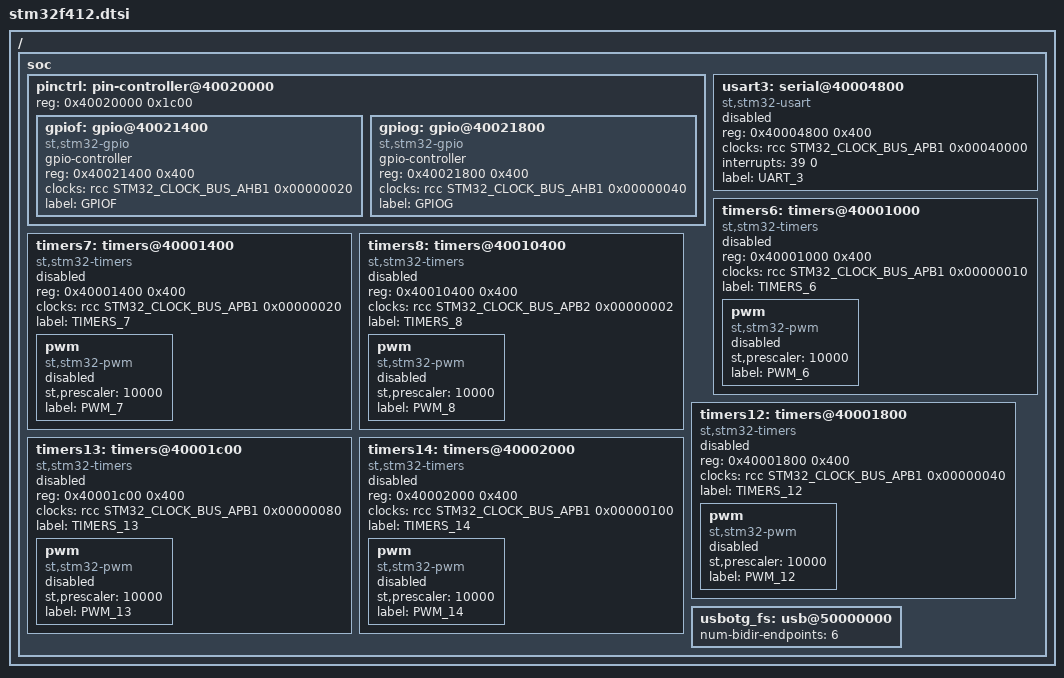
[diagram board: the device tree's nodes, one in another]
/*
 * Copyright (c) 2017 Florian Vaussard, HEIG-VD
 *
 * SPDX-License-Identifier: Apache-2.0
 */

#include <st/stm32f412-pinctrl.dtsi>
#include <st/stm32f411.dtsi>

/ {
	soc {
		pinctrl: pin-controller@40020000 {
			reg = <0x40020000 0x1c00>;

			gpiof: gpio@40021400 {
				compatible = "st,stm32-gpio";
				gpio-controller;
				#gpio-cells = <2>;
				reg = <0x40021400 0x400>;
				clocks = <&rcc STM32_CLOCK_BUS_AHB1 0x00000020>;
				label = "GPIOF";
			};

			gpiog: gpio@40021800 {
				compatible = "st,stm32-gpio";
				gpio-controller;
				#gpio-cells = <2>;
				reg = <0x40021800 0x400>;
				clocks = <&rcc STM32_CLOCK_BUS_AHB1 0x00000040>;
				label = "GPIOG";
			};
		};

		usart3: serial@40004800 {
			compatible = "st,stm32-usart", "st,stm32-uart";
			reg = <0x40004800 0x400>;
			clocks = <&rcc STM32_CLOCK_BUS_APB1 0x00040000>;
			interrupts = <39 0>;
			status = "disabled";
			label = "UART_3";
		};

		timers6: timers@40001000 {
			compatible = "st,stm32-timers";
			reg = <0x40001000 0x400>;
			clocks = <&rcc STM32_CLOCK_BUS_APB1 0x00000010>;
			status = "disabled";
			label = "TIMERS_6";

			pwm {
				compatible = "st,stm32-pwm";
				status = "disabled";
				st,prescaler = <10000>;
				label = "PWM_6";
			};
		};

		timers7: timers@40001400 {
			compatible = "st,stm32-timers";
			reg = <0x40001400 0x400>;
			clocks = <&rcc STM32_CLOCK_BUS_APB1 0x00000020>;
			status = "disabled";
			label = "TIMERS_7";

			pwm {
				compatible = "st,stm32-pwm";
				status = "disabled";
				st,prescaler = <10000>;
				label = "PWM_7";
			};
		};

		timers8: timers@40010400 {
			compatible = "st,stm32-timers";
			reg = <0x40010400 0x400>;
			clocks = <&rcc STM32_CLOCK_BUS_APB2 0x00000002>;
			status = "disabled";
			label = "TIMERS_8";

			pwm {
				compatible = "st,stm32-pwm";
				status = "disabled";
				st,prescaler = <10000>;
				label = "PWM_8";
			};
		};

		timers12: timers@40001800 {
			compatible = "st,stm32-timers";
			reg = <0x40001800 0x400>;
			clocks = <&rcc STM32_CLOCK_BUS_APB1 0x00000040>;
			status = "disabled";
			label = "TIMERS_12";

			pwm {
				compatible = "st,stm32-pwm";
				status = "disabled";
				st,prescaler = <10000>;
				label = "PWM_12";
			};
		};

		timers13: timers@40001c00 {
			compatible = "st,stm32-timers";
			reg = <0x40001c00 0x400>;
			clocks = <&rcc STM32_CLOCK_BUS_APB1 0x00000080>;
			status = "disabled";
			label = "TIMERS_13";

			pwm {
				compatible = "st,stm32-pwm";
				status = "disabled";
				st,prescaler = <10000>;
				label = "PWM_13";
			};
		};

		timers14: timers@40002000 {
			compatible = "st,stm32-timers";
			reg = <0x40002000 0x400>;
			clocks = <&rcc STM32_CLOCK_BUS_APB1 0x00000100>;
			status = "disabled";
			label = "TIMERS_14";

			pwm {
				compatible = "st,stm32-pwm";
				status = "disabled";
				st,prescaler = <10000>;
				label = "PWM_14";
			};
		};

		usbotg_fs: usb@50000000 {
			num-bidir-endpoints = <6>;
		};
	};
};
